# NUC400_v1 register map
File version: 1.0
Registers are 32-bit, read-write, reset 0x0 unless marked. A register's access mark holds for its fields unless they carry their own. Offsets are from the block's base; [hi:lo] are bit positions.

## QEI0 — QEI Register Map
Base 0x400B0000
Same registers: QEI1 0x400B1000
0x00 QEI_CNT — QEI Pulse Counter
  [31:0] VAL — Quadrature Encoder Pulse Counter. A 32-bit up/down counter. When an effective phase pulse is detected, this counter is increased by one if the bit DIRF (QEI_STATUS[8]) is one or decreased by one if the bit DIRF is zero. This register performs an integrator which count value is proportional to the encoder position. The pulse counter may be initialized to a predetermined value by one of three events occurs:
0x04 QEI_CNTHOLD — QEI Pulse Counter Hold Register
  [31:0] VAL — Quadrature Encoder Pulse Counter Hold Register. When bit HOLDCNT (QEIx_CTL[24]) goes from low to high, the QEI_CNT value is copied into QEI_CNTHOLD register.
0x08 QEI_CNTLATCH — QEI Pulse Counter Index Latch Register
  [31:0] VAL — Quadrature Encoder Pulse Counter Index Latch. When the IDXF (QEI_STATUS[0]) bit is set, the QEI_CNT value is copied into QEI_CNTLATCH register.
0x0C QEI_CNTCMP — QEI Pulse Counter Compare Register
  [31:0] VAL — Quadrature Encoder Pulse Counter Compare
0x14 QEI_CNTMAX — QEI Pre-set Maximum Count Register
  [31:0] VAL — Quadrature Encoder Preset Maximum Count. This register value determined by user stores the maximum value which may be the number of the quadrature encoder pulses in a revolution for the QEI controller compare-counting mode.
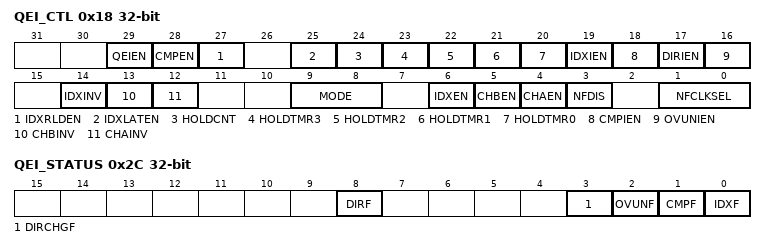
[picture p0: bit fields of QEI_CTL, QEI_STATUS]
0x18 QEI_CTL — QEI Controller Control Register
  [29] QEIEN — Quadrature Encoder Interface Controller Enable Bit
    0=QEI controller function Disabled; 1=QEI controller function Enabled
  [28] CMPEN — The Compare Function Enable Bit. The compare function in QEI controller is to compare the dynamic counting QEI_CNT with the compare register QEI_CNTCMP, if QEI_CNT value reaches QEI_CNTCMP, the flag CMPF will be set.
    0=Compare function Disabled; 1=Compare function Enabled
  [27] IDXRLDEN — Index Trigger QEI_CNT Reload Enable Bit
    0=Reload function Disabled; 1=QEI_CNT re-initialized by Index signal Enabled
  [25] IDXLATEN — Index Latch QEI_CNT Enable Bit. If this bit is set to high, the QEI_CNT content will be latched into QEI_CNTLATCH at every rising on signal CHX.
    0=The index signal latch QEI counter function Disabled; 1=The index signal latch QEI counter function Enabled
  [24] HOLDCNT — Hold QEI_CNT Control. When this bit is set from low to high, the QEI_CNT value is copied into QEI_CNTHOLD. This bit may be set by writing 1 to it or Timer0~Timer3 interrupt flag TIF (TIMERx_INTSTS[0]). Note: This bit is automatically cleared after QEI_CNTHOLD holds QEI_CNT value.
    0=No operation; 1=QEI_CNT content is captured and stored in QEI_CNTHOLD
  [23] HOLDTMR3 — Hold QEI_CNT By Timer 3
    0=TIF (TIMER3_INTSTS[0]) has no effect on HOLDCNT; 1=A rising edge of bit TIF(TIMER3_INTSTS[0]) in timer 3 sets HOLDCNT to 1
  [22] HOLDTMR2 — Hold QEI_CNT By Timer 2
    0=TIF(TIMER2_INTSTS[0]) has no effect on HOLDCNT; 1=A rising edge of bit TIF(TIMER2_INTSTS[0]) in timer 2 sets HOLDCNT to 1
  [21] HOLDTMR1 — Hold QEI_CNT By Timer 1
    0=TIF(TIMER1_INTSTS[0]) has no effect on HOLDCNT; 1=A rising edge of bit TIF (TIMER1_INTSTS[0]) in timer 1 sets HOLDCNT to 1
  [20] HOLDTMR0 — Hold QEI_CNT By Timer 0
    0=TIF (TIMER0_INTSTS[0]) has no effect on HOLDCNT; 1=A rising edge of bit TIF(TIMER0_INTSTS[0]) in timer 0 sets HOLDCNT to 1
  [19] IDXIEN — IDXF Trigger QEI Interrupt Enable Bit
    0=The IDXF can trigger QEI interrupt Disabled; 1=The IDXF can trigger QEI interrupt Enabled
  [18] CMPIEN — CMPF Trigger QEI Interrupt Enable Bit
    0=CMPF can trigger QEI controller interrupt Disabled; 1=CMPF can trigger QEI controller interrupt Enabled
  [17] DIRIEN — DIRCHGF Trigger QEI Interrupt Enable Bit
    0=DIRCHGF can trigger QEI controller interrupt Disabled; 1=DIRCHGF can trigger QEI controller interrupt Enabled
  [16] OVUNIEN — OVUNF Trigger QEI Interrupt Enable Bit
    0=OVUNF can trigger QEI controller interrupt Disabled; 1=OVUNF can trigger QEI controller interrupt Enabled
  [14] IDXINV — Inverse IDX Input Polarity
    0=Not inverse IDX input polarity; 1=IDX input polarity is inversed to QEI controller
  [13] CHBINV — Inverse QEB Input Polarity
    0=Not inverse QEB input polarity; 1=QEB input polarity is inversed to QEI controller
  [12] CHAINV — Inverse QEA Input Polarity
    0=Not inverse QEA input polarity; 1=QEA input polarity is inversed to QEI controller
  [9:8] MODE — QEI Counting Mode Selection. There are four quadrature encoder pulse counter operation modes.
    0=X4 Free-counting Mode; 1=X2 Free-counting Mode; 2=X4 Compare-counting Mode; 3=X2 Compare-counting Mode
  [6] IDXEN — IDX Input To QEI Controller Enable Bit
    0=IDX input to QEI Controller Disabled; 1=IDX input to QEI Controller Enabled
  [5] CHBEN — QEB Input To QEI Controller Enable Bit
    0=QEB input to QEI Controller Disabled; 1=QEB input to QEI Controller Enabled
  [4] CHAEN — QEA Input To QEI Controller Enable Bit
    0=QEA input to QEI Controller Disabled; 1=QEA input to QEI Controller Enabled
  [3] NFDIS — QEI Controller Input Noise Filter Disable Bit
    0=The noise filter of QEI controller Enabled; 1=The noise filter of QEI controller Disabled
  [1:0] NFCLKSEL — Noise Filter Clock Pre-Divide Selection. To determine the sampling frequency of the Noise Filter clock .
    0=QEI_CLK; 1=QEI_CLK/2; 2=QEI_CLK/4; 3=QEI_CLK/16
0x2C QEI_STATUS — QEI Controller Status Register
  [8] DIRF — QEI Counter Counting Direction Indication. Note: This bit is set/reset by hardware according to the phase detection between CHA and CHB.
    0=QEI Counter is in down-counting; 1=QEI Counter is in up-counting
  [3] DIRCHGF — Direction Change Flag. Flag is set by hardware while QEI counter counting direction is changed. Software can clear this bit by writing 1 to it. Note: This bit is only cleared by writing 1 to it.
    0=No change in QEI counter counting direction; 1=QEI counter counting direction is changed
  [2] OVUNF — QEI Counter Overflow Or Underflow Flag. Flag is set by hardware while QEI_CNT overflows from 0xFFFF_FFFF to zero in free-counting mode or from the QEI_CNTMAX value to zero in compare-counting mode. Similarly, the flag is set wile QEI counter underflows from zero to 0xFFFF_FFFF or QEI_CNTMAX. Note: This bit is only cleared by writing 1 to it.
    0=No overflow or underflow occurs in QEI counter; 1=QEI counter occurs counting overflow or underflow
  [1] CMPF — Compare-Match Flag. If the QEI compare function is enabled, the flag is set by hardware while QEI counter up or down counts and reach to the QEI_CNTCMP value. Note: This bit is only cleared by writing 1 to it.
    0=QEI counter does not match with QEI_CNTCMP value; 1=QEI counter counts to the same as QEI_CNTCMP value
  [0] IDXF — IDX Detected Flag. When the QEI controller detects a rising edge on signal CHX it will set flag IDXF to high. Note: This bit is only cleared by writing 1 to it.
    0=No rising edge detected on signal CHX; 1=A rising edge occurs on signal CHX
